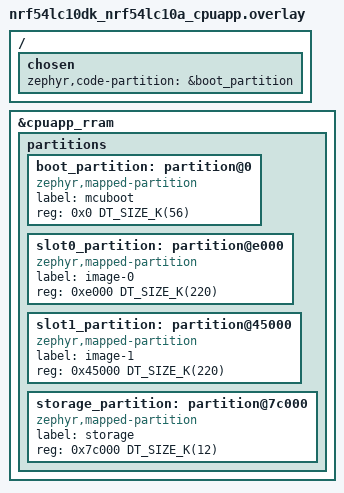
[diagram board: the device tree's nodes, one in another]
/delete-node/ &boot_partition;
/delete-node/ &slot0_partition;
/delete-node/ &slot1_partition;
/delete-node/ &storage_partition;

&cpuapp_rram {
	partitions {
		boot_partition: partition@0 {
			compatible = "zephyr,mapped-partition";
			label = "mcuboot";
			reg = <0x0 DT_SIZE_K(56)>;
		};

		slot0_partition: partition@e000 {
			compatible = "zephyr,mapped-partition";
			label = "image-0";
			reg = <0xe000 DT_SIZE_K(220)>;
		};

		slot1_partition: partition@45000 {
			compatible = "zephyr,mapped-partition";
			label = "image-1";
			reg = <0x45000 DT_SIZE_K(220)>;
		};

		storage_partition: partition@7c000 {
			compatible = "zephyr,mapped-partition";
			label = "storage";
			reg = <0x7c000 DT_SIZE_K(12)>;
		};
	};
};

/ {
	chosen {
		zephyr,code-partition = &boot_partition;
	};
};
